# ATtiny840 device description
Architecture: AVR8; Family: tinyAVR
Registers are 8-bit, access not given, no defined reset value unless marked. A register's access mark holds for its fields unless they carry their own. Offsets are from the block's base; [hi:lo] are bit positions.

## TC3 (TC16 module) — Timer/Counter, 16-bit
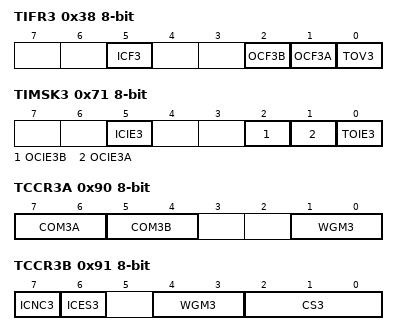
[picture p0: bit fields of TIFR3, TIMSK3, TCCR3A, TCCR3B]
0x38 TIFR3 — Timer/Counter Interrupt Flag register
  [5] ICF3 — Input Capture Flag 1
  [2] OCF3B — Output Compare Flag 1B
  [1] OCF3A — Output Compare Flag 1A
  [0] TOV3 — Timer/Counter3 Overflow Flag
0x71 TIMSK3 — Timer/Counter3 Interrupt Mask Register
  [5] ICIE3 — Timer/Counter3 Input Capture Interrupt Enable
  [2] OCIE3B — Timer/Counter3 Output CompareB Match Interrupt Enable
  [1] OCIE3A — Timer/Counter3 Output CompareA Match Interrupt Enable
  [0] TOIE3 — Timer/Counter3 Overflow Interrupt Enable
0x90 TCCR3A — Timer/Counter3 Control Register A
  [7:6] COM3A — Compare Output Mode 3A, bits
  [5:4] COM3B — Compare Output Mode 3B, bits
  [1:0] WGM3 — Waveform Generation Mode
0x91 TCCR3B — Timer/Counter3 Control Register B
  [7] ICNC3 — Input Capture 3 Noise Canceler
  [6] ICES3 — Input Capture 3 Edge Select
  [4:3] WGM3 (bit 2 of the value upward) — Waveform Generation Mode
  [2:0] CS3 — Prescaler source of Timer/Counter 3
    0=No Clock Source (Stopped); 1=Running, No Prescaling; 2=Running, CLK/8; 3=Running, CLK/64; 4=Running, CLK/256; 5=Running, CLK/1024; 6=Running, ExtClk Tx Falling Edge; 7=Running, ExtClk Tx Rising Edge
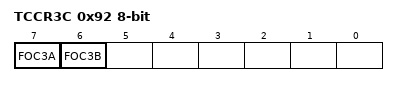
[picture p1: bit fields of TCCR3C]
0x92 TCCR3C — Timer/Counter3 Control Register C
  [7] FOC3A, [6] FOC3B
0x94 TCNT1 16-bit — Timer/Counter3 Bytes
0x96 ICR3 16-bit — Timer/Counter3 Input Capture Register Bytes
0x98 OCR3A 16-bit — Timer/Counter3 Output Compare Register Bytes
0x9A OCR3B 16-bit — Timer/Counter3 Output Compare Register Bytes

## TC2 (TC8_ASYNC module) — Timer/Counter, 8-bit Async
Instances: TC2 0x00
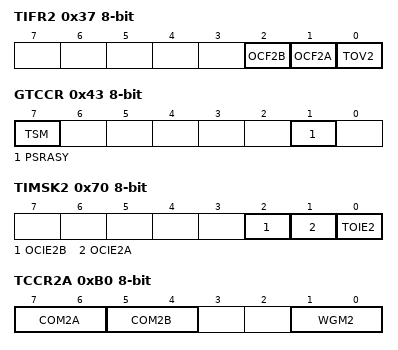
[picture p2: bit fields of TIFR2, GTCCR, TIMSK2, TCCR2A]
0x37 TIFR2 — Timer/Counter2 Interrupt Flag Register
  [2] OCF2B — Output Compare Flag 2B
  [1] OCF2A — Output Compare Flag 2A
  [0] TOV2 — Timer/Counter2 Overflow Flag
0x43 GTCCR — General Timer Counter Control register
  [7] TSM — Timer/Counter Synchronization Mode
  [1] PSRASY — Prescaler Reset Timer/Counter2
0x70 TIMSK2 — Timer/Counter2 Interrupt Mask register
  [2] OCIE2B — Timer/Counter2 Output Compare Match B Interrupt Enable
  [1] OCIE2A — Timer/Counter2 Output Compare Match A Interrupt Enable
  [0] TOIE2 — Timer/Counter2 Overflow Interrupt Enable
0xB0 TCCR2A — Timer/Counter2 Control Register A
  [7:6] COM2A — Compare Output Mode bits
  [5:4] COM2B — Compare Output Mode bits
  [1:0] WGM2 — Waveform Genration Mode
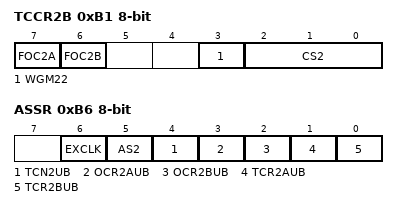
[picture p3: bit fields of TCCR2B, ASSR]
0xB1 TCCR2B — Timer/Counter2 Control Register B
  [7] FOC2A — Force Output Compare A
  [6] FOC2B — Force Output Compare B
  [3] WGM22 — Waveform Generation Mode
  [2:0] CS2 — Clock Select bits
    0=No Clock Source (Stopped); 1=Running, No Prescaling; 2=Running, CLK/8; 3=Running, CLK/32; 4=Running, CLK/64; 5=Running, CLK/128; 6=Running, CLK/256; 7=Running, CLK/1024
0xB2 TCNT2 — Timer/Counter2
0xB3 OCR2A — Timer/Counter2 Output Compare Register A
0xB4 OCR2B — Timer/Counter2 Output Compare Register B
0xB6 ASSR — Asynchronous Status Register
  [6] EXCLK — Enable External Clock Input
  [5] AS2 — Asynchronous Timer/Counter2
  [4] TCN2UB — Timer/Counter2 Update Busy
  [3] OCR2AUB — Output Compare Register2 Update Busy
  [2] OCR2BUB — Output Compare Register 2 Update Busy
  [1] TCR2AUB — Timer/Counter Control Register2 Update Busy
  [0] TCR2BUB — Timer/Counter Control Register2 Update Busy

## AC — Analog Comparator
Instances: AC 0x00
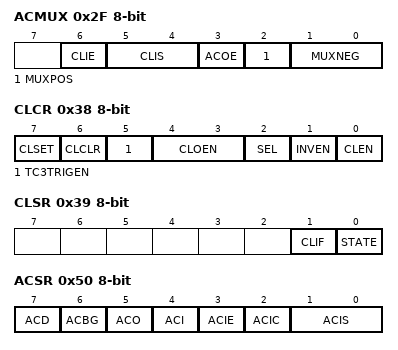
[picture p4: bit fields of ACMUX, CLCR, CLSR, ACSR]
0x2F ACMUX — Analog Comparator Mux register
  [6] CLIE — Custom Logic Interrupt Enable
  [5:4] CLIS — Custom Logic Interrupt Select
    1=Interrupt on Toggle; 2=Interrupt on Falling Edge; 3=Interrupt on Rising Edge
  [3] ACOE — Analog Comparator Output Enable
  [2] MUXPOS — Analog Comparator Positive input select
  [1:0] MUXNEG — Analog Comparator Negative input select
0x38 CLCR — Custom Logic Control Register
  [7] CLSET — Custom Logic Set
  [6] CLCLR — Custom Logic Clear
  [5] TC3TRIGEN — Custom Logic Trigger Timer/Counter 3
  [4:3] CLOEN — Custom Logic Output Enable
  [2] SEL — Custom Logic Demux Select
  [1] INVEN — Custom Logic Inverter Enable
  [0] CLEN — Custom Logic Enable
0x39 CLSR — Custom Logic Status Register
  [1] CLIF — Custom Logic Interrupt Flag
  [0] STATE — Custom Logic Latch State
0x50 ACSR — Analog Comparator Control And Status Register
  [7] ACD — Analog Comparator Disable
  [6] ACBG — Analog Comparator Bandgap Select
  [5] ACO — Analog Compare Output
  [4] ACI — Analog Comparator Interrupt Flag
  [3] ACIE — Analog Comparator Interrupt Enable
  [2] ACIC — Analog Comparator Input Capture Enable
  [1:0] ACIS — Analog Comparator Interrupt Mode Select bits
    0=Interrupt on Toggle; 2=Interrupt on Falling Edge; 3=Interrupt on Rising Edge
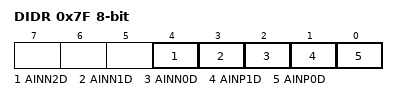
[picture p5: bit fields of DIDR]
0x7F DIDR — Digital Input Disable Register 1
  [4] AINN2D — AINN2 Digital Input Disable
  [3] AINN1D — AINN1 Digital Input Disable
  [2] AINN0D — AINN0 Digital Input Disable
  [1] AINP1D — AINP1 Digital Input Disable
  [0] AINP0D — AINP0 Digital Input Disable
